# YTM32Z1LS0 register map
Vendor: YTMicro; File version: 1.2
CPU: CM0PLUS r0p1, little endian, MPU, FPU, 2 interrupt priority bits
Registers are 32-bit, read-write, reset 0x0 unless marked. A register's access mark holds for its fields unless they carry their own. Offsets are from the block's base; [hi:lo] are bit positions; 'fields as' and 'values as' point back to an identical list.

## CIM — Chip Integration Module
Base 0x40048000; register names take the prefix CIM_
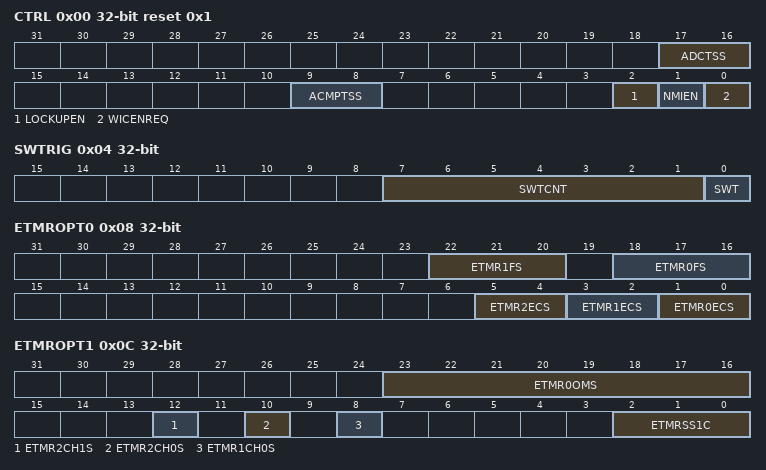
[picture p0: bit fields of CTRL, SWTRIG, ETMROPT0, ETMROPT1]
0x00 CTRL reset 0x1
  [17:16] ADCTSS wo — Select ADC input trigger synchronized mode.
    0=Input trigger is raw signal; 1=Input trigger is synchronized signal, synchronized by bus clock; 2=Input trigger is synchronized signal, synchronized by functional clock
  [9:8] ACMPTSS wo — Select ACMP input trigger synchronized mode.
    values as ADCTSS
  [2] LOCKUPEN — Enable CPU Lockup Reset.
    0=CPU Lockup reset is disabled; 1=CPU Lockup reset is enabled
  [1] NMIEN — Enable NMI function.
    0=NMI is disabled; 1=NMI is enabled
  [0] WICENREQ — Enable WIC to wakeup low power mode.
    0=Disable WIC to wakeup low power mode; 1=Enable WIC to wakeup low power mode
0x04 SWTRIG
  [7:1] SWTCNT — Define software trigger valid length (multiplied with bus clock cycle), SWTCNT value will decrease until equal to zero when SWT set.
  [0] SWT — Generate software trigger.
    0=Software trigger is disabled; 1=Generate software trigger and it keeps until SWTCNT equals to zero
0x08 ETMROPT0
  [22:20] ETMR1FS — Select fault source for ETMR1. 0b000 - ETMR1 fault 0 input from pad. 0b001 - ETMR1 fault 0 input from TMU. 0b000 - ETMR1 fault 1 input from pad. 0b010 - ETMR1 fault 1 input from TMU. 0b000 - ETMR1 fault 2 input from pad. 0b100 - ETMR1 fault 2 input from TMU.
  [18:16] ETMR0FS — Select fault source for ETMR0. 0b000 - ETMR0 fault 0 input from pad. 0b001 - ETMR0 fault 0 input from TMU. 0b000 - ETMR0 fault 1 input from pad. 0b010 - ETMR0 fault 1 input from TMU. 0b000 - ETMR0 fault 2 input from pad. 0b100 - ETMR0 fault 2 input from TMU.
  [5:4] ETMR2ECS — Select external clock source for ETMR2.
    0=Select TCLK_IN0 input as external clock for ETMR2; 1=Select TCLK_IN1 input as external clock for ETMR2; 2=Select TCLK_IN2 input as external clock for ETMR2
  [3:2] ETMR1ECS — Select external clock source for ETMR1.
    0=Select TCLK_IN0 input as external clock for ETMR1; 1=Select TCLK_IN1 input as external clock for ETMR1; 2=Select TCLK_IN2 input as external clock for ETMR1
  [1:0] ETMR0ECS — Select external clock source for ETMR0.
    0=Select TCLK_IN0 input as external clock for ETMR0; 1=Select TCLK_IN1 input as external clock for ETMR0; 2=Select TCLK_IN2 input as external clock for ETMR0
0x0C ETMROPT1
  [23:16] ETMR0OMS — Select modulation with ETMR1_CH1 for ETMR0 channels. 0b00000000 - ETMR0 channel 0 output to pad directly. 0b00000001 - ETMR0 channel 0 output modulation with ETMR1_CH1 output. 0b00000000 - ETMR0 channel 1 output to pad directly. 0b00000010 - ETMR0 channel 1 output modulation with ETMR1_CH1 output. 0b00000000 - ETMR0 channel 2 output to pad directly. 0b00000100 - ETMR0 channel 2 output modulation with ETMR1_CH1 output. 0b00000000 - ETMR0 channel 3 output to pad directly. 0b00001000 - ETMR0 channel 3 output modulation with ETMR1_CH1 output. 0b00000000 - ETMR0 channel 4 output to pad directly. 0b00010000 - ETMR0 channel 4 output modulation with ETMR1_CH1 output. 0b00000000 - ETMR0 channel 5 output to pad directly. 0b00100000 - ETMR0 channel 5 output modulation with ETMR1_CH1 output. 0b00000000 - ETMR0 channel 6 output to pad directly. 0b01000000 - ETMR0 channel 6 output modulation with ETMR1_CH1 output. 0b00000000 - ETMR0 channel 7 output to pad directly. 0b10000000 - ETMR0 channel 7 output modulation with ETMR1_CH1 output.
  [12] ETMR2CH1S — Select input source for ETMR2 channel 1.
    0=ETMR2 channel 1 input from pad; 1=ETMR2 channel 1 input from XOR result(ETMR2_CH0, ETMR2_CH1, ETMR1_CH1)
  [10] ETMR2CH0S — Select input source for ETMR2 channel 0.
    0=ETMR2 channel 0 input from pad; 1=ETMR2 channel 0 input from ACMP out
  [8] ETMR1CH0S — Select input source for ETMR1 channel 0.
    0=ETMR1 channel 0 input from pad; 1=ETMR1 channel 0 input from ACMP out
  [2:0] ETMRSS1C — Generate synchronize signal for ETMR trigger 1. 0b000 - Don't generate synchronize signal for ETMR0 trigger 1. 0b001 - Generate synchronize signal for ETMR0 trigger 1. 0b000 - Don't generate synchronize signal for ETMR1 trigger 1. 0b010 - Generate synchronize signal for ETMR1 trigger 1. 0b000 - Don't generate synchronize signal for ETMR2 trigger 1. 0b100 - Generate synchronize signal for ETMR2 trigger 1.
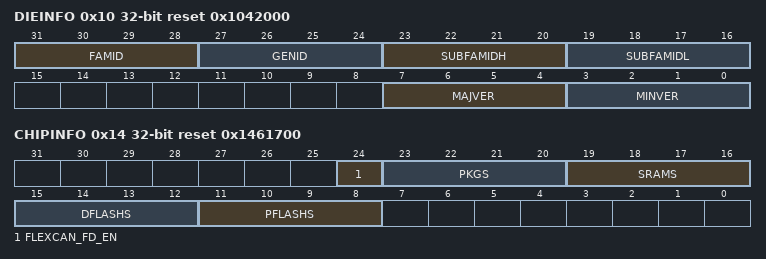
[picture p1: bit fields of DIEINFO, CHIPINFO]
0x10 DIEINFO ro reset 0x1042000
  [31:28] FAMID — Describe the product family information.
    0=B - Basic(General); 1=D - Dashboard; 2=P - Powertrain; 3=V - Vision; 4=N - Networks
  [27:24] GENID — Describe the product generation information.
    1=1st generation production; 2=2nd generation production; 3=3rd generation production
  [23:20] SUBFAMIDH — Describe the product sub family information.
    0=L - Low end; 1=M - Middle end; 2=H - High end
  [19:16] SUBFAMIDL — Describe the product max Flash size information.
    0=A - 64KB; 1=B - 128KB; 2=C - 256KB; 3=D - 512KB; 4=E - 1MB
  [7:4] MAJVER — Describe the major version information.
  [3:0] MINVER — Describe the minor version information.
0x14 CHIPINFO ro reset 0x1461700
  [24] FLEXCAN_FD_EN — FlexCAN FD Feature Enable/Disable
    0=FlexCAN FD Feature is disabled; 1=FlexCAN FD Feature is enable
  [23:20] PKGS — Describe chip package type information.
    0=16 TSOP; 1=20 TSOP/32 LQFP; 2=32 QFN; 3=48 LQFP; 4=64 LQFP; 8=100 LQFP/MAPBGA; 10=144 LQFP; 12=176 LQFP; 13=257 BGA; 15=289 BGA
  [19:16] SRAMS — Describe sram size information.
    2=1KB; 3=2KB; 4=4KB; 5=8KB; 6=16KB; 7=32KB; 8=64KB; 9=128KB; 10=256KB; 11=512KB; 12=1MB; 13=2MB; 14=4MB; 15=8MB
  [15:12] DFLASHS — Describe data flash size information.
    0=1KB; 1=2KB; 2=4KB; 3=8KB; 4=16KB; 5=32KB; 6=64KB; 7=128KB; 8=256KB; 9=512KB
  [11:8] PFLASHS — Describe program flash size information.
    0=1KB; 1=2KB; 2=4KB; 3=8KB; 4=16KB; 5=32KB; 6=64KB; 7=128KB; 8=256KB; 9=512KB; 10=1MB; 11=2MB; 12=4MB; 13=8MB; 14=16MB; 15=32MB
